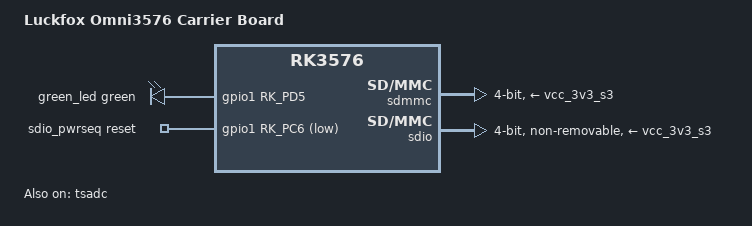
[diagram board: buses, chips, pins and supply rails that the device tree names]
// SPDX-License-Identifier: (GPL-2.0+ OR MIT)
/*
 * Copyright (c) 2024 Rockchip Electronics Co., Ltd.
 * Copyright (c) 2025 John Clark <inindev@gmail.com>
 */

/dts-v1/;

#include "rk3576-luckfox-core3576.dtsi"

/ {
	model = "Luckfox Omni3576 Carrier Board";
	compatible = "luckfox,omni3576", "luckfox,core3576", "rockchip,rk3576";

	aliases {
		mmc1 = &sdmmc;
	};

	leds: leds {
		compatible = "gpio-leds";
		pinctrl-names = "default";
		pinctrl-0 = <&led_green_pin>;

		green_led: green-led {
			color = <LED_COLOR_ID_GREEN>;
			function = LED_FUNCTION_HEARTBEAT;
			gpios = <&gpio1 RK_PD5 GPIO_ACTIVE_HIGH>;
			linux,default-trigger = "heartbeat";
		};
	};

	sdio_pwrseq: sdio-pwrseq {
		compatible = "mmc-pwrseq-simple";
		clocks = <&hym8563>;
		clock-names = "ext_clock";
		pinctrl-names = "default";
		pinctrl-0 = <&wifi_reg_on>;
		reset-gpios = <&gpio1 RK_PC6 GPIO_ACTIVE_LOW>;
		status = "okay";
	};

	tsadc: tsadc@2ae70000 {
		compatible = "rockchip,rk3576-tsadc";
		reg = <0x0 0x2ae70000 0x0 0x400>;
		interrupts = <GIC_SPI 123 IRQ_TYPE_LEVEL_HIGH>;
		clocks = <&cru CLK_TSADC>, <&cru PCLK_TSADC>;
		clock-names = "tsadc", "apb_pclk";
		assigned-clocks = <&cru CLK_TSADC>;
		assigned-clock-rates = <2000000>;
		resets = <&cru SRST_TSADC>, <&cru SRST_P_TSADC>;
		reset-names = "tsadc", "tsadc-apb";
		#thermal-sensor-cells = <1>;
		rockchip,hw-tshut-temp = <120000>;
		rockchip,hw-tshut-mode = <0>; /* tshut mode 0:CRU 1:GPIO */
		rockchip,hw-tshut-polarity = <0>; /* tshut polarity 0:LOW 1:HIGH */
		status = "okay";
	};

};

&pinctrl {
	leds {
		led_green_pin: led-green-pin {
			rockchip,pins = <1 RK_PD5 RK_FUNC_GPIO &pcfg_pull_none>;
		};
	};

	wireless-wlan {
		wifi_wake_host: wifi-wake-host {
			rockchip,pins = <0 RK_PB0 RK_FUNC_GPIO &pcfg_pull_down>;
		};

		wifi_reg_on: wifi-reg-on {
			rockchip,pins = <1 RK_PC6 RK_FUNC_GPIO &pcfg_pull_none>;
		};
	};
};

&sdmmc {
	bus-width = <4>;
	cap-mmc-highspeed;
	cap-sd-highspeed;
	disable-wp;
	no-sdio;
	sd-uhs-sdr104;
	vmmc-supply = <&vcc_3v3_s3>;
	vqmmc-supply = <&vccio_sd_s0>;
	status = "okay";
	/delete-property/ supports-cqe;
};


&sdio {
	bus-width = <4>;
	cap-sdio-irq;
	disable-wp;
	keep-power-in-suspend;
	mmc-pwrseq = <&sdio_pwrseq>;
	no-sd;
	no-mmc;
	non-removable;
	sd-uhs-sdr50;
	sd-uhs-sdr104;
	cap-sd-highspeed;
	vmmc-supply = <&vcc_3v3_s3>;
	vqmmc-supply = <&vccio_sd_s0>;
	wakeup-source;
	status = "okay";
};
